VERSION ""

NS_ :

BS_:

BU_:
VAL_TABLE_ Drive_Overload 1 "Enable" 0 "Disable" ;
VAL_TABLE_ Sports_Mode 1 "Sports Mode Enable" 0 "Sports Mode Disable" ;
VAL_TABLE_ City_Mode 1 "City Mode Enable" 0 "City Mode Disable" ;
VAL_TABLE_ Fault_enable_Disable 1 "Enable" 0 "Disable" ;
VAL_TABLE_ Brake_Command 1 "Brake On" 0 "Brake Off" ;
VAL_TABLE_ Trip_reset 255 "Reset" 0 "Not reset" ;
VAL_TABLE_ eco_sports_mode 1 "sports mode" 0 "eco mode" ;
VAL_TABLE_ Invalid_BMS_data 3 "Regen current out of range" 2 "Drive current out of range" 1 "SOC out of range" ;
VAL_TABLE_ Vehicle_power_mode 2 "Sport" 1 "Eco" ;
VAL_TABLE_ Vehicle_status2 2 "MCU_ready" 1 "Low_bus_voltage" 0 "Regeneratio " ;
VAL_TABLE_ status 1 "Enable" 0 "Disable" ;
VAL_TABLE_ Vehicle_status 4 "Reverse" 2 "Forward" 1 "Park" 0 "Neutral" ;
VAL_TABLE_ Motor_Error 17 "Motor overspeed" 16 "Motor output phase loss" 15 "Rotary T/F Failure" 14 "Controller power undervoltage" 13 "Controller high temperature" 12 "Motor high temperature" 11 "Motor overload" 10 "Overcurrent" 9 "Open-circuit" 8 "Short-circuit" 7 "Undervoltage" 6 "Overvoltage" 5 "Self Inspection abnormality" 4 "Normal" 3 "Three level fault" 2 "Two level fault" 1 "One level fault" 0 "Normal" ;
VAL_TABLE_ Motor_Status 9 "Error" 8 "Normal" 7 "Get_Ready" 6 "Initialization" 5 "Reverse" 4 "Forward" 3 "Brake/Regen" 2 "Drive" 1 "Run" 0 "Stop" ;

BO_ 3221225472 VECTOR__INDEPENDENT_SIG_MSG: 0 Vector__XXX
 SG_ FAn_command : 0|8@1+ (1,0) [0|255] "" Vector__XXX
 SG_ Drive_overload : 0|1@1+ (1,0) [0|1] "" Vector__XXX
 SG_ MCU_Error_Code : 0|8@1+ (1,0) [0|255] "" Vector__XXX
 SG_ Invalid_BMS_data : 0|8@1+ (1,0) [0|255] "" Vector__XXX
 SG_ Vehicle_Power_mode : 0|8@1+ (1,0) [0|255] "" Vector__XXX
 SG_ FAN_Status : 0|1@1+ (1,0) [0|1] "" Vector__XXX
 SG_ DC_Current : 0|16@1- (1,0) [-32768|32767] "Adc" Vector__XXX
 SG_ NewSignal_0014 : 0|8@1+ (1,0) [0|0] "" Vector__XXX
 SG_ OCD_ERROR : 0|8@1+ (1,0) [0|0] "" Vector__XXX
 SG_ OV_ERROR : 0|1@1+ (1,0) [0|1] "" Vector__XXX
 SG_ UV_ERROR : 0|1@1+ (1,0) [0|1] "" Vector__XXX
 SG_ CMU1_CV_6 : 0|8@1+ (1,0) [0|0] "" Vector__XXX

BO_ 1801 New_Message_14: 8 Vector__XXX
 SG_ Fault_historic_details : 0|64@1+ (1,0) [0|255] "" Vector__XXX

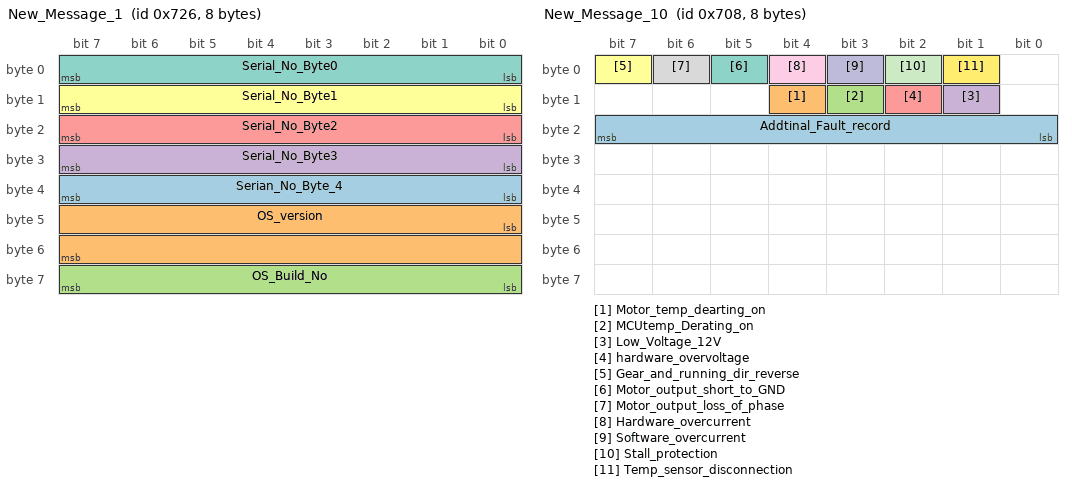
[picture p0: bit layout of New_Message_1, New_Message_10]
BO_ 1830 New_Message_1: 8 Vector__XXX
 SG_ Serian_No_Byte_4 : 32|8@1+ (1,0) [0|0] "" Vector__XXX
 SG_ OS_version : 40|16@1+ (1,0) [0|65535] "" Vector__XXX
 SG_ OS_Build_No : 56|8@1+ (1,0) [0|255] "" Vector__XXX
 SG_ Serial_No_Byte3 : 24|8@1+ (1,0) [0|255] "" Vector__XXX
 SG_ Serial_No_Byte2 : 16|8@1+ (1,0) [0|255] "" Vector__XXX
 SG_ Serial_No_Byte1 : 8|8@1+ (1,0) [0|255] "" Vector__XXX
 SG_ Serial_No_Byte0 : 0|8@1+ (1,0) [0|255] "" Vector__XXX

BO_ 1831 New_Message_11: 8 Vector__XXX
 SG_ Sports_mode : 1|1@1+ (1,0) [0|1] "" Vector__XXX
 SG_ City_Mode : 0|1@1+ (1,0) [0|1] "" Vector__XXX

BO_ 1800 New_Message_10: 8 Vector__XXX
 SG_ Addtinal_Fault_record : 16|8@1+ (1,0) [0|255] "" Vector__XXX
 SG_ Motor_temp_dearting_on : 12|1@1+ (1,0) [0|1] "" Vector__XXX
 SG_ MCUtemp_Derating_on : 11|1@1+ (1,0) [0|1] "" Vector__XXX
 SG_ Low_Voltage_12V : 9|1@1+ (1,0) [0|1] "" Vector__XXX
 SG_ hardware_overvoltage : 10|1@1+ (1,0) [0|1] "" Vector__XXX
 SG_ Gear_and_running_dir_reverse : 7|1@1+ (1,0) [0|1] "" Vector__XXX
 SG_ Motor_output_short_to_GND : 5|1@1+ (1,0) [0|1] "" Vector__XXX
 SG_ Motor_output_loss_of_phase : 6|1@1+ (1,0) [0|1] "" Vector__XXX
 SG_ Hardware_overcurrent : 4|1@1+ (1,0) [0|1] "" Vector__XXX
 SG_ Software_overcurrent : 3|1@1+ (1,0) [0|1] "" Vector__XXX
 SG_ Stall_protection : 2|1@1+ (1,0) [0|1] "" Vector__XXX
 SG_ Temp_sensor_disconnection : 1|1@1+ (1,0) [0|1] "" Vector__XXX

BO_ 298 New_Message_12: 8 Vector__XXX
 SG_ DYN_Limit_I_IN : 0|16@1+ (0.1,0) [0|6553.5] "Amp" Vector__XXX
 SG_ DYN_LIM_I_OUT : 16|16@1+ (0.1,0) [0|6553.5] "Amp" Vector__XXX

BO_ 1828 New_Message_8: 8 Vector__XXX
 SG_ Motor_Torque_Estimated : 0|16@1- (0.1,0) [-3276.8|3276.7] "NM" Vector__XXX

BO_ 1815 New_Message_7: 8 Vector__XXX
 SG_ Operating_frequency : 0|16@1- (1,0) [-32768|32767] "Hz" Vector__XXX

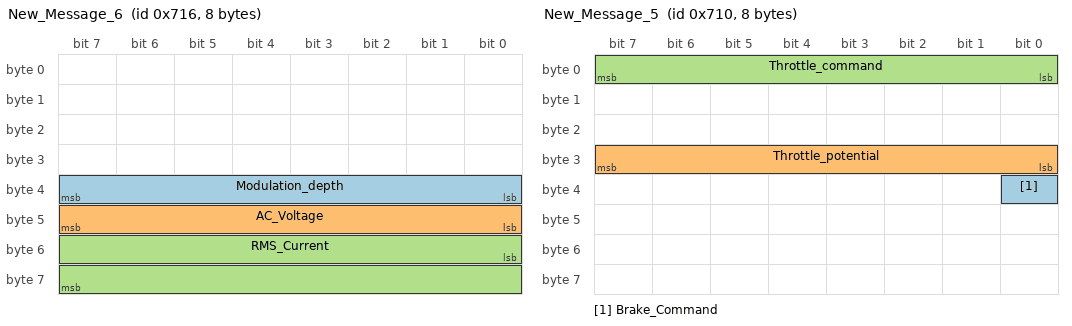
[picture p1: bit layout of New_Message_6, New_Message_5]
BO_ 1814 New_Message_6: 8 Vector__XXX
 SG_ Modulation_depth : 32|8@1+ (1,0) [0|0] "%" Vector__XXX
 SG_ AC_Voltage : 40|8@1+ (1,0) [0|255] "V rms" Vector__XXX
 SG_ RMS_Current : 48|16@1+ (1,0) [0|65535] "" Vector__XXX

BO_ 1808 New_Message_5: 8 Vector__XXX
 SG_ Brake_Command : 32|1@1+ (1,0) [0|1] "" Vector__XXX
 SG_ Throttle_potential : 24|8@1+ (0.1,0) [0|25.5] "" Vector__XXX
 SG_ Throttle_command : 0|8@1+ (1,0) [0|255] "%" Vector__XXX

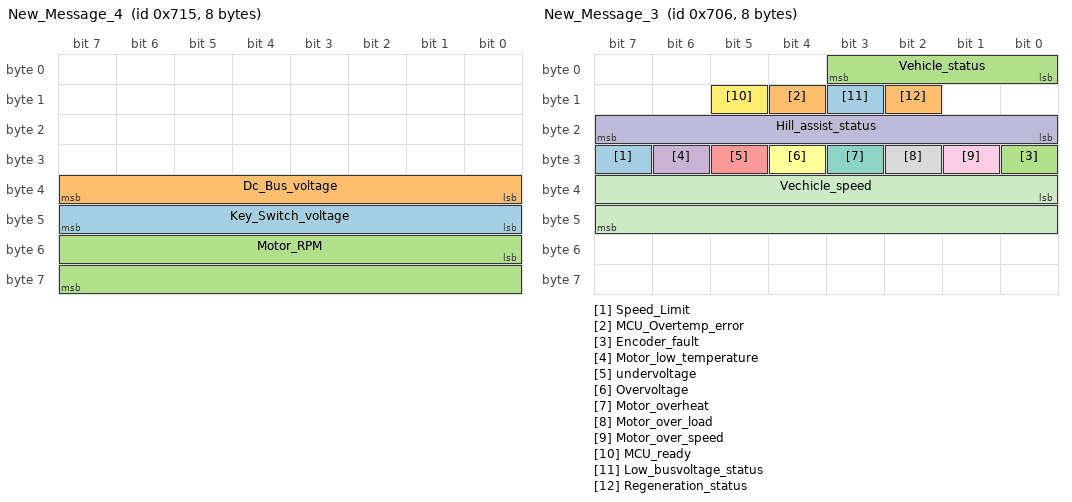
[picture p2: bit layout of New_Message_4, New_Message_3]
BO_ 1813 New_Message_4: 8 Vector__XXX
 SG_ Key_Switch_voltage : 40|8@1+ (1,0) [0|24] "" Vector__XXX
 SG_ Dc_Bus_voltage : 32|8@1+ (1,0) [0|255] "Volt" Vector__XXX
 SG_ Motor_RPM : 48|16@1+ (1,0) [0|65535] "" Vector__XXX

BO_ 1798 New_Message_3: 8 Vector__XXX
 SG_ Speed_Limit : 31|1@1+ (1,0) [0|1] "" Vector__XXX
 SG_ MCU_Overtemp_error : 12|1@1+ (1,0) [0|1] "" Vector__XXX
 SG_ Encoder_fault : 24|1@1+ (1,0) [0|1] "" Vector__XXX
 SG_ Motor_low_temperature : 30|1@1+ (1,0) [0|1] "" Vector__XXX
 SG_ undervoltage : 29|1@1+ (1,0) [0|1] "" Vector__XXX
 SG_ Overvoltage : 28|1@1+ (1,0) [0|1] "" Vector__XXX
 SG_ Motor_overheat : 27|1@1+ (1,0) [0|1] "" Vector__XXX
 SG_ Motor_over_load : 26|1@1+ (1,0) [0|1] "" Vector__XXX
 SG_ Motor_over_speed : 25|1@1+ (1,0) [0|0] "" Vector__XXX
 SG_ Hill_assist_status : 16|8@1+ (1,0) [0|255] "" Vector__XXX
 SG_ Vechicle_speed : 32|16@1- (0.1,0) [-3276.8|3276.7] "Kmph" Vector__XXX
 SG_ MCU_ready : 13|1@1+ (1,0) [0|1] "" Vector__XXX
 SG_ Low_busvoltage_status : 11|1@1+ (1,0) [0|0] "" Vector__XXX
 SG_ Regeneration_status : 10|1@1+ (1,0) [0|1] "" Vector__XXX
 SG_ Vehicle_status : 0|4@1+ (1,0) [0|15] "" Vector__XXX

BO_ 1797 New_Message_2: 8 Vector__XXX
 SG_ MCU_Temperature : 8|8@1+ (1,-50) [-50|205] "" Vector__XXX
 SG_ Motor_Temperature : 0|8@1+ (1,-50) [-50|205] "" Vector__XXX

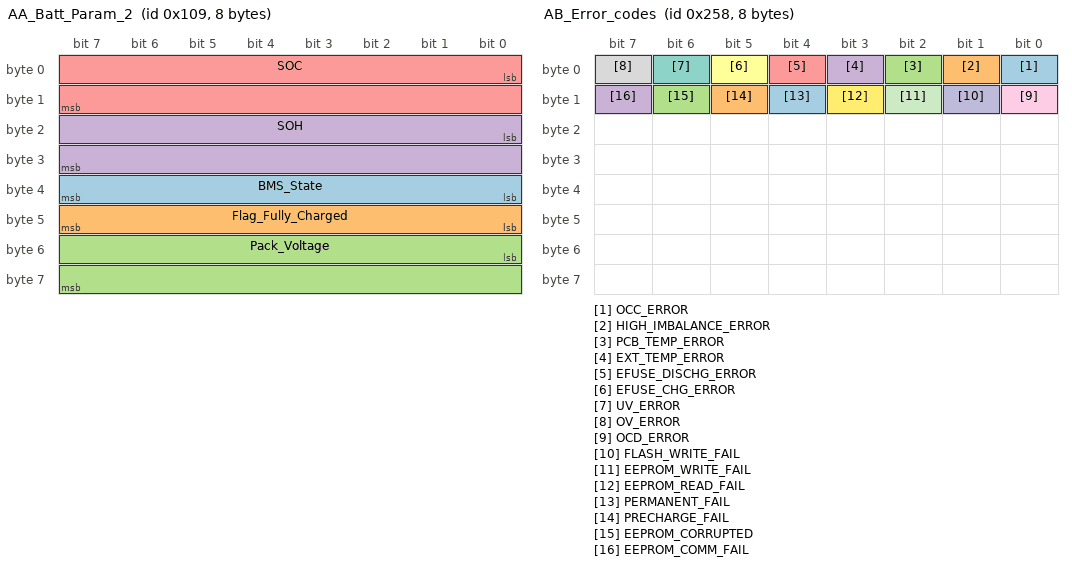
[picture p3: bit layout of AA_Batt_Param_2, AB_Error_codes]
BO_ 265 AA_Batt_Param_2: 8 Vector__XXX
 SG_ BMS_State : 32|8@1+ (1,0) [0|5] "" Vector__XXX
 SG_ Flag_Fully_Charged : 40|8@1+ (1,0) [0|1] "" Vector__XXX
 SG_ Pack_Voltage : 48|16@1+ (0.1,0) [60|85] "V" Vector__XXX
 SG_ SOH : 16|16@1+ (0.01,0) [0|100] "%" Vector__XXX
 SG_ SOC : 0|16@1+ (0.01,0) [0|100] "%" Vector__XXX

BO_ 600 AB_Error_codes: 8 Vector__XXX
 SG_ OCC_ERROR : 0|1@1+ (1,0) [0|1] "" Vector__XXX
 SG_ HIGH_IMBALANCE_ERROR : 1|1@1+ (1,0) [0|1] "" Vector__XXX
 SG_ PCB_TEMP_ERROR : 2|1@1+ (1,0) [0|1] "" Vector__XXX
 SG_ EXT_TEMP_ERROR : 3|1@1+ (1,0) [0|1] "" Vector__XXX
 SG_ EFUSE_DISCHG_ERROR : 4|1@1+ (1,0) [0|1] "" Vector__XXX
 SG_ EFUSE_CHG_ERROR : 5|1@1+ (1,0) [0|1] "" Vector__XXX
 SG_ UV_ERROR : 6|1@1+ (1,0) [0|1] "" Vector__XXX
 SG_ OV_ERROR : 7|1@1+ (1,0) [0|1] "" Vector__XXX
 SG_ OCD_ERROR : 8|1@1+ (1,0) [0|1] "" Vector__XXX
 SG_ FLASH_WRITE_FAIL : 9|1@1+ (1,0) [0|1] "" Vector__XXX
 SG_ EEPROM_WRITE_FAIL : 10|1@1+ (1,0) [0|1] "" Vector__XXX
 SG_ EEPROM_READ_FAIL : 11|1@1+ (1,0) [0|1] "" Vector__XXX
 SG_ PERMANENT_FAIL : 12|1@1+ (1,0) [0|1] "" Vector__XXX
 SG_ PRECHARGE_FAIL : 13|1@1+ (1,0) [0|1] "" Vector__XXX
 SG_ EEPROM_CORRUPTED : 14|1@1+ (1,0) [0|1] "" Vector__XXX
 SG_ EEPROM_COMM_FAIL : 15|1@1+ (1,0) [0|1] "" Vector__XXX

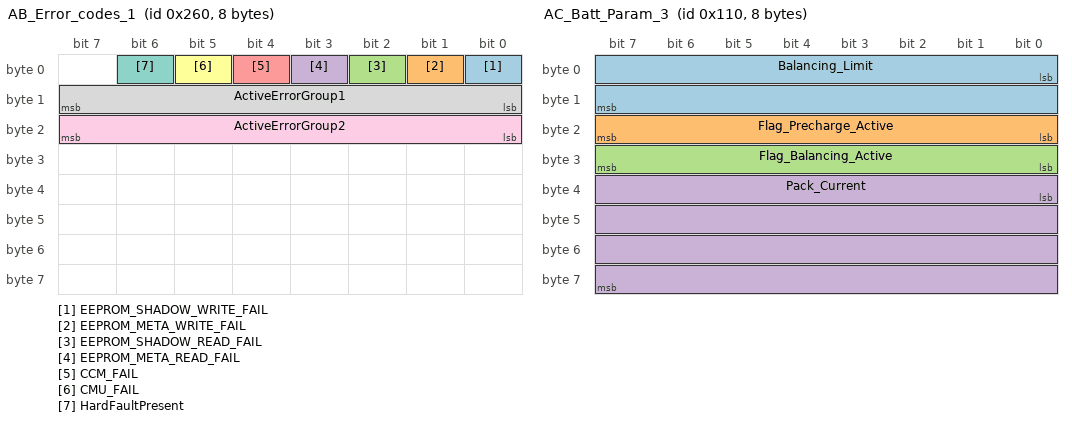
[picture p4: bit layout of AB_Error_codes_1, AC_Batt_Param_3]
BO_ 608 AB_Error_codes_1: 8 Vector__XXX
 SG_ EEPROM_SHADOW_WRITE_FAIL : 0|1@1+ (1,0) [0|1] "" Vector__XXX
 SG_ EEPROM_META_WRITE_FAIL : 1|1@1+ (1,0) [0|1] "" Vector__XXX
 SG_ EEPROM_SHADOW_READ_FAIL : 2|1@1+ (1,0) [0|1] "" Vector__XXX
 SG_ EEPROM_META_READ_FAIL : 3|1@1+ (1,0) [0|1] "" Vector__XXX
 SG_ CCM_FAIL : 4|1@1+ (1,0) [0|1] "" Vector__XXX
 SG_ CMU_FAIL : 5|1@1+ (1,0) [0|1] "" Vector__XXX
 SG_ HardFaultPresent : 6|1@1+ (1,0) [0|1] "" Vector__XXX
 SG_ ActiveErrorGroup1 : 8|8@1+ (1,0) [0|255] "" Vector__XXX
 SG_ ActiveErrorGroup2 : 16|8@1+ (1,0) [0|255] "" Vector__XXX

BO_ 272 AC_Batt_Param_3: 8 Vector__XXX
 SG_ Balancing_Limit : 0|16@1+ (0.1,0) [0|4200] "mV" Vector__XXX
 SG_ Flag_Precharge_Active : 16|8@1+ (1,0) [0|1] "" Vector__XXX
 SG_ Flag_Balancing_Active : 24|8@1+ (1,0) [0|1] "" Vector__XXX
 SG_ Pack_Current : 32|32@1- (1E-05,0) [-1000|1000] "A" Vector__XXX

BO_ 263 AC_ChargerID: 8 Vector__XXX
 SG_ ChargerVoltage : 7|16@0+ (0.1,0) [0|6553.5] "Voltage" Vector__XXX
 SG_ ChargerCurrent : 23|16@0+ (0.1,0) [0|6553.5] "Amps" Vector__XXX

BO_ 1542 AuxVoltage: 8 Vector__XXX
 SG_ AuxVoltage : 15|16@0+ (0.01,0) [0|65535] "V" Vector__XXX

BO_ 284 BalancingMasks: 8 Vector__XXX
 SG_ BalancingMaskGroup1 : 32|16@1+ (1,0) [0|65535] "" Vector__XXX
 SG_ BalancingMaskGroup2 : 48|8@1+ (1,0) [0|0] "" Vector__XXX

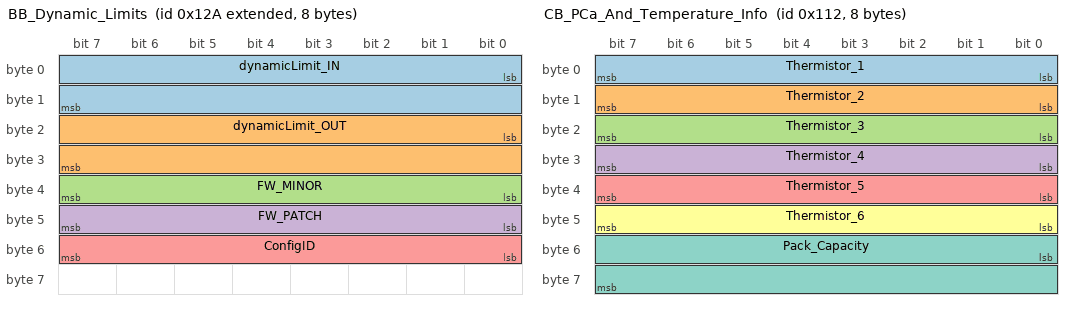
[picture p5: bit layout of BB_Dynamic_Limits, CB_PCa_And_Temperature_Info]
BO_ 2147483946 BB_Dynamic_Limits: 8 Vector__XXX
 SG_ dynamicLimit_IN : 0|16@1- (0.1,0) [-3776.8|3276] "A" Vector__XXX
 SG_ dynamicLimit_OUT : 16|16@1- (0.1,3) [-3276.8|3276] "A" Vector__XXX
 SG_ FW_MINOR : 32|8@1+ (1,0) [0|0] "" Vector__XXX
 SG_ FW_PATCH : 40|8@1+ (1,0) [0|0] "" Vector__XXX
 SG_ ConfigID : 48|8@1- (1,0) [-128|127] "" Vector__XXX

BO_ 342 BC_Dynamic_inst: 8 Vector__XXX
 SG_ dynamicLimitIn_Inst : 0|16@1- (0.1,0) [-3276.8|3276] "" Vector__XXX
 SG_ dynamicLimitOut_Inst : 16|16@1- (0.1,0) [-3276.8|3276.8] "" Vector__XXX

BO_ 296 BF_CCM_CMU_Counter: 8 Vector__XXX
 SG_ mcu_counter : 16|16@1+ (1,0) [0|65535] "" Vector__XXX
 SG_ cycleCount : 48|16@1+ (1,0) [0|65535] "" Vector__XXX

BO_ 274 CB_PCa_And_Temperature_Info: 8 Vector__XXX
 SG_ Thermistor_1 : 0|8@1- (1,0) [-128|127] "C" Vector__XXX
 SG_ Thermistor_2 : 8|8@1- (1,0) [-128|127] "C" Vector__XXX
 SG_ Thermistor_3 : 16|8@1- (1,0) [-128|127] "C" Vector__XXX
 SG_ Thermistor_4 : 24|8@1- (1,0) [-128|127] "C" Vector__XXX
 SG_ Thermistor_5 : 32|8@1- (1,0) [-128|127] "C" Vector__XXX
 SG_ Thermistor_6 : 40|8@1- (1,0) [-128|127] "C" Vector__XXX
 SG_ Pack_Capacity : 48|16@1- (0.01,0) [-327.68|327.68] "Ah" Vector__XXX

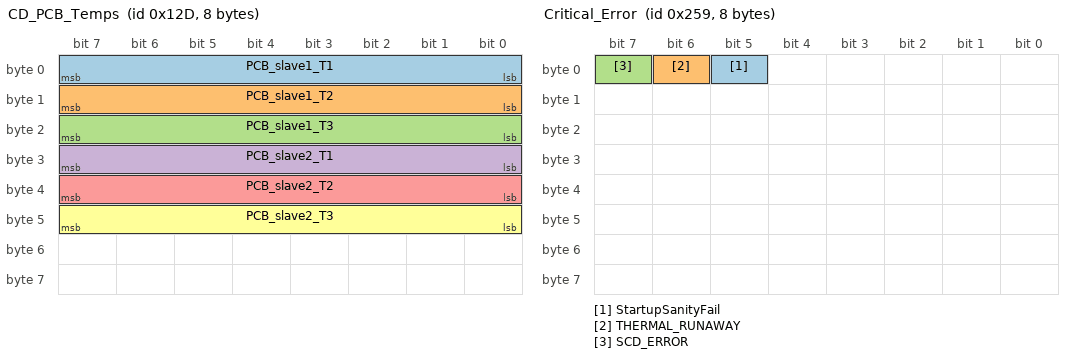
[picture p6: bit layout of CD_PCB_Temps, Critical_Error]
BO_ 301 CD_PCB_Temps: 8 Vector__XXX
 SG_ PCB_slave1_T1 : 0|8@1- (1,0) [-128|127] "C" Vector__XXX
 SG_ PCB_slave1_T2 : 8|8@1- (1,0) [-128|127] "C" Vector__XXX
 SG_ PCB_slave1_T3 : 16|8@1- (1,0) [-128|127] "C" Vector__XXX
 SG_ PCB_slave2_T1 : 24|8@1- (1,0) [-128|127] "C" Vector__XXX
 SG_ PCB_slave2_T2 : 32|8@1- (1,0) [-128|127] "C" Vector__XXX
 SG_ PCB_slave2_T3 : 40|8@1- (1,0) [-128|127] "C" Vector__XXX

BO_ 601 Critical_Error: 8 Vector__XXX
 SG_ StartupSanityFail : 5|1@1- (1,0) [0|1] "" Vector__XXX
 SG_ THERMAL_RUNAWAY : 6|1@1- (1,0) [0|1] "" Vector__XXX
 SG_ SCD_ERROR : 7|1@1- (1,0) [0|1] "" Vector__XXX

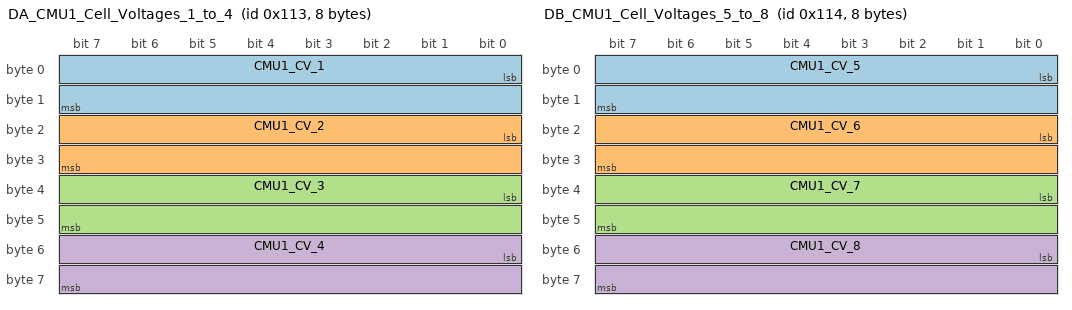
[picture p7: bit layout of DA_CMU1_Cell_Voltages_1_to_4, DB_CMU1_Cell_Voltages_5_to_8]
BO_ 275 DA_CMU1_Cell_Voltages_1_to_4: 8 Vector__XXX
 SG_ CMU1_CV_1 : 0|16@1+ (0.1,0) [3100|4200] "mV" Vector__XXX
 SG_ CMU1_CV_2 : 16|16@1+ (0.1,0) [3100|4200] "mV" Vector__XXX
 SG_ CMU1_CV_3 : 32|16@1+ (0.1,0) [3100|4200] "mV" Vector__XXX
 SG_ CMU1_CV_4 : 48|16@1+ (0.1,0) [3100|4200] "mV" Vector__XXX

BO_ 276 DB_CMU1_Cell_Voltages_5_to_8: 8 Vector__XXX
 SG_ CMU1_CV_5 : 0|16@1+ (0.1,0) [3100|4200] "mV" Vector__XXX
 SG_ CMU1_CV_6 : 16|16@1+ (0.1,0) [3100|4200] "mV" Vector__XXX
 SG_ CMU1_CV_7 : 32|16@1+ (0.1,0) [3100|4200] "mV" Vector__XXX
 SG_ CMU1_CV_8 : 48|16@1+ (0.1,0) [3100|4200] "mV" Vector__XXX

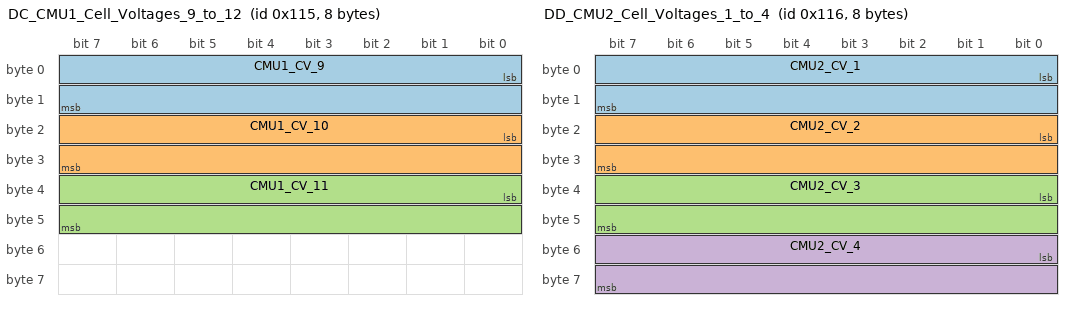
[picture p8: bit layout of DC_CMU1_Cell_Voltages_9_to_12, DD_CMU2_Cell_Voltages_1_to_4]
BO_ 277 DC_CMU1_Cell_Voltages_9_to_12: 8 Vector__XXX
 SG_ CMU1_CV_9 : 0|16@1+ (0.1,0) [3100|4200] "mv" Vector__XXX
 SG_ CMU1_CV_10 : 16|16@1+ (0.1,0) [3100|4200] "mV" Vector__XXX
 SG_ CMU1_CV_11 : 32|16@1- (0.1,0) [3100|4200] "mV" Vector__XXX

BO_ 278 DD_CMU2_Cell_Voltages_1_to_4: 8 Vector__XXX
 SG_ CMU2_CV_1 : 0|16@1+ (0.1,0) [3100|4200] "mV" Vector__XXX
 SG_ CMU2_CV_2 : 16|16@1+ (0.1,0) [3100|4200] "mV" Vector__XXX
 SG_ CMU2_CV_3 : 32|16@1+ (0.1,0) [3100|4200] "mV" Vector__XXX
 SG_ CMU2_CV_4 : 48|16@1+ (0.1,0) [3100|4200] "mV" Vector__XXX

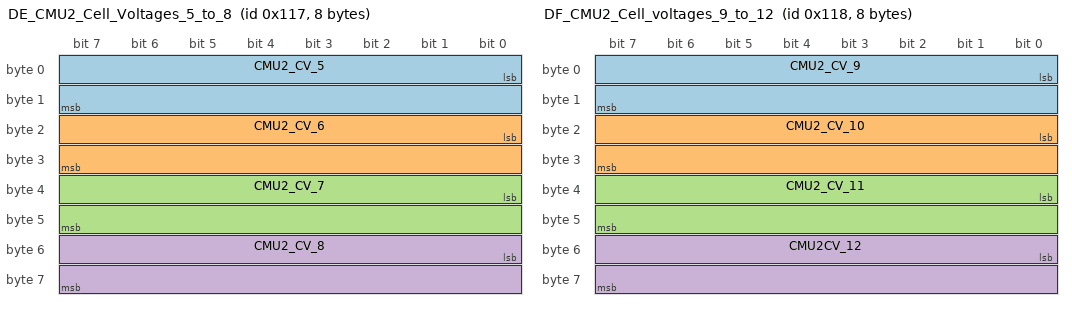
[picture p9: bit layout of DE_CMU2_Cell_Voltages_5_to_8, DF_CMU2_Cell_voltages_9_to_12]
BO_ 279 DE_CMU2_Cell_Voltages_5_to_8: 8 Vector__XXX
 SG_ CMU2_CV_5 : 0|16@1+ (0.1,0) [3100|4200] "mV" Vector__XXX
 SG_ CMU2_CV_6 : 16|16@1+ (0.1,0) [3100|4200] "mV" Vector__XXX
 SG_ CMU2_CV_7 : 32|16@1+ (0.1,0) [3100|4200] "mV" Vector__XXX
 SG_ CMU2_CV_8 : 48|16@1+ (0.1,0) [3100|4200] "mV" Vector__XXX

BO_ 280 DF_CMU2_Cell_voltages_9_to_12: 8 Vector__XXX
 SG_ CMU2_CV_9 : 0|16@1+ (0.1,0) [3100|4200] "mV" Vector__XXX
 SG_ CMU2_CV_10 : 16|16@1+ (0.1,0) [3100|4200] "mV" Vector__XXX
 SG_ CMU2_CV_11 : 32|16@1+ (0.1,0) [3100|4200] "mV" Vector__XXX
 SG_ CMU2CV_12 : 48|16@1+ (0.1,0) [3100|4200] "mV" Vector__XXX

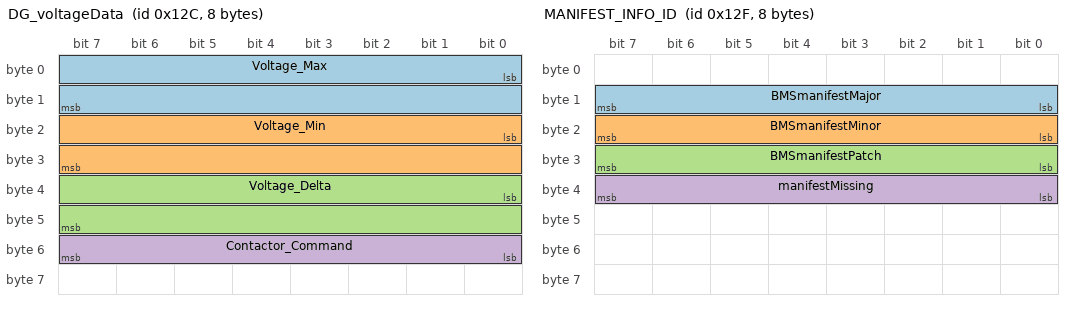
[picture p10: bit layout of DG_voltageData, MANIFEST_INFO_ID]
BO_ 300 DG_voltageData: 8 Vector__XXX
 SG_ Voltage_Max : 0|16@1+ (0.1,0) [0|65535] "mV" Vector__XXX
 SG_ Voltage_Min : 16|16@1+ (0.1,0) [0|65535] "mV" Vector__XXX
 SG_ Voltage_Delta : 32|16@1+ (0.1,0) [0|65535] "mV" Vector__XXX
 SG_ Contactor_Command : 48|8@1+ (0.1,0) [0|255] "" Vector__XXX

BO_ 302 IR_PARAM_1: 8 Vector__XXX
 SG_ IR_Value : 0|32@1+ (1E-05,0) [-21474.83648|21474.83647] "" Vector__XXX

BO_ 303 MANIFEST_INFO_ID: 8 Vector__XXX
 SG_ BMSmanifestMajor : 8|8@1+ (1,0) [0|255] "" Vector__XXX
 SG_ BMSmanifestMinor : 16|8@1+ (1,0) [0|255] "" Vector__XXX
 SG_ BMSmanifestPatch : 24|8@1+ (1,0) [0|255] "" Vector__XXX
 SG_ manifestMissing : 32|8@1+ (1,0) [0|255] "" Vector__XXX

BO_ 1954 Short_Circuit_Detect: 8 Vector__XXX
 SG_ SCD_Flag : 56|8@1+ (1,0) [0|255] "" Vector__XXX

BO_ 1538 Vehicle_State: 8 Vector__XXX
 SG_ VehicleState : 56|8@1+ (1,0) [0|255] "" Vector__XXX

CM_ BO_ 3221225472 "This is a message for not used signals, created by Vector CANdb++ DBC OLE DB Provider.";
BA_DEF_ SG_  "SigType" ENUM  "Default","Range","RangeSigned","ASCII","Discrete","Control","ReferencePGN","DTC","StringDelimiter","StringLength","StringLengthControl","MessageCounter","MessageChecksum";
BA_DEF_ SG_  "GenSigEVName" STRING ;
BA_DEF_ SG_  "GenSigILSupport" ENUM  "No","Yes";
BA_DEF_ SG_  "GenSigSendType" ENUM  "Cyclic","OnWrite","OnWriteWithRepetition","OnChange","OnChangeWithRepetition","IfActive","IfActiveWithRepetition","NoSigSendType";
BA_DEF_ SG_  "GenSigStartValue" INT 0 2147483647;
BA_DEF_ BO_  "GenMsgILSupport" ENUM  "No","Yes";
BA_DEF_ BU_  "NmStationAddress" INT 0 255;
BA_DEF_ BO_  "GenMsgSendType" ENUM  "cyclic","NotUsed","IfActive","NotUsed","NotUsed","NotUsed","NotUsed","NotUsed","noMsgSendType";
BA_DEF_ BO_  "GenMsgRequestable" INT 0 1;
BA_DEF_  "DBName" STRING ;
BA_DEF_  "BusType" STRING ;
BA_DEF_  "ProtocolType" STRING ;
BA_DEF_ BO_  "VFrameFormat" ENUM  "StandardCAN","ExtendedCAN","reserved","J1939PG";
BA_DEF_DEF_  "SigType" "Default";
BA_DEF_DEF_  "GenSigEVName" "Env@Nodename_@Signame";
BA_DEF_DEF_  "GenSigILSupport" "Yes";
BA_DEF_DEF_  "GenSigSendType" "NoSigSendType";
BA_DEF_DEF_  "GenSigStartValue" 0;
BA_DEF_DEF_  "GenMsgILSupport" "Yes";
BA_DEF_DEF_  "NmStationAddress" 254;
BA_DEF_DEF_  "GenMsgSendType" "noMsgSendType";
BA_DEF_DEF_  "GenMsgRequestable" 1;
BA_DEF_DEF_  "DBName" "";
BA_DEF_DEF_  "BusType" "CAN";
BA_DEF_DEF_  "ProtocolType" "J1939";
BA_DEF_DEF_  "VFrameFormat" "J1939PG";
BA_ "DBName" "D03CAN";
BA_ "VFrameFormat" BO_ 1801 0;
BA_ "VFrameFormat" BO_ 1830 0;
BA_ "VFrameFormat" BO_ 1831 0;
BA_ "VFrameFormat" BO_ 1800 0;
BA_ "VFrameFormat" BO_ 298 0;
BA_ "VFrameFormat" BO_ 1828 0;
BA_ "VFrameFormat" BO_ 1815 0;
BA_ "VFrameFormat" BO_ 1814 0;
BA_ "VFrameFormat" BO_ 1808 0;
BA_ "VFrameFormat" BO_ 1813 0;
BA_ "VFrameFormat" BO_ 1798 0;
BA_ "VFrameFormat" BO_ 1797 0;
BA_ "VFrameFormat" BO_ 265 0;
BA_ "VFrameFormat" BO_ 600 0;
BA_ "VFrameFormat" BO_ 608 0;
BA_ "VFrameFormat" BO_ 272 0;
BA_ "VFrameFormat" BO_ 263 0;
BA_ "VFrameFormat" BO_ 1542 0;
BA_ "VFrameFormat" BO_ 284 0;
BA_ "VFrameFormat" BO_ 342 0;
BA_ "VFrameFormat" BO_ 296 0;
BA_ "VFrameFormat" BO_ 274 0;
BA_ "VFrameFormat" BO_ 301 0;
BA_ "VFrameFormat" BO_ 601 0;
BA_ "VFrameFormat" BO_ 275 0;
BA_ "VFrameFormat" BO_ 276 0;
BA_ "VFrameFormat" BO_ 277 0;
BA_ "VFrameFormat" BO_ 278 0;
BA_ "VFrameFormat" BO_ 279 0;
BA_ "VFrameFormat" BO_ 280 0;
BA_ "VFrameFormat" BO_ 300 0;
BA_ "VFrameFormat" BO_ 302 0;
BA_ "VFrameFormat" BO_ 303 0;
BA_ "VFrameFormat" BO_ 1954 0;
BA_ "VFrameFormat" BO_ 1538 0;
BA_ "GenSigStartValue" SG_ 1797 MCU_Temperature 50;
BA_ "GenSigStartValue" SG_ 1797 Motor_Temperature 50;
VAL_ 1831 Sports_mode 1 "Sports Mode Enable" 0 "Sports Mode Disable" ;
VAL_ 1831 City_Mode 1 "City Mode Enable" 0 "City Mode Disable" ;
VAL_ 1800 Motor_temp_dearting_on 1 "Enable" 0 "Disable" ;
VAL_ 1800 MCUtemp_Derating_on 1 "Enable" 0 "Disable" ;
VAL_ 1800 Low_Voltage_12V 1 "Enable" 0 "Disable" ;
VAL_ 1800 Gear_and_running_dir_reverse 1 "Enable" 0 "Disable" ;
VAL_ 1800 Motor_output_short_to_GND 1 "Enable" 0 "Disable" ;
VAL_ 1800 Motor_output_loss_of_phase 1 "Enable" 0 "Disable" ;
VAL_ 1800 Hardware_overcurrent 1 "Enable" 0 "Disable" ;
VAL_ 1800 Software_overcurrent 1 "Enable" 0 "Disable" ;
VAL_ 1800 Stall_protection 1 "Enable" 0 "Disable" ;
VAL_ 1800 Temp_sensor_disconnection 1 "Enable" 0 "Disable" ;
VAL_ 1808 Brake_Command 1 "Brake On" 0 "Brake Off" ;
VAL_ 1798 Speed_Limit 1 "Enable" 0 "Disable" ;
VAL_ 1798 MCU_Overtemp_error 1 "Enable" 0 "Disable" ;
VAL_ 1798 Encoder_fault 1 "Enable" 0 "Disable" ;
VAL_ 1798 Motor_low_temperature 1 "Enable" 0 "Disable" ;
VAL_ 1798 undervoltage 1 "Enable" 0 "Disable" ;
VAL_ 1798 Overvoltage 1 "Enable" 0 "Disable" ;
VAL_ 1798 Motor_overheat 1 "Enable" 0 "Disable" ;
VAL_ 1798 Motor_over_load 1 "Enable" 0 "Disable" ;
VAL_ 1798 Motor_over_speed 1 "Enable" 0 "Disable" ;
VAL_ 1798 MCU_ready 1 "Enable" 0 "Disable" ;
VAL_ 1798 Low_busvoltage_status 1 "Enable" 0 "Disable" ;
VAL_ 1798 Regeneration_status 1 "Enable" 0 "Disable" ;
VAL_ 1798 Vehicle_status 8 "Forward(Sports Mode)" 4 "Reverse" 2 "Forward(City Mode)" 1 "Neutral" ;
